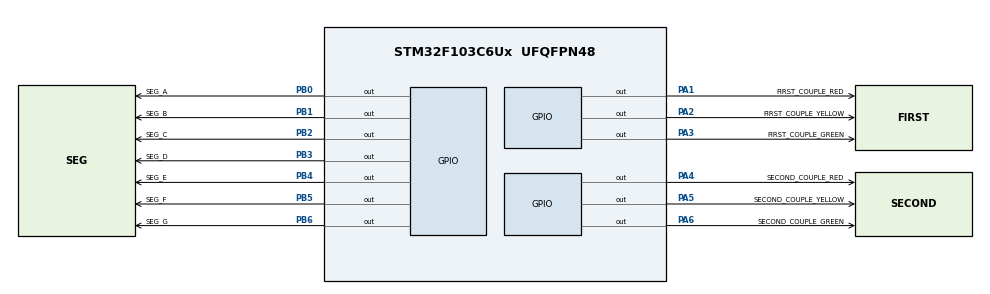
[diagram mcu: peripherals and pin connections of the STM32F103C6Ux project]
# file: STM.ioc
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Mcu.Family=STM32F1
Mcu.Name=STM32F103C6Ux
Mcu.Package=UFQFPN48
NVIC.PriorityGroup=NVIC_PRIORITYGROUP_4
PA1.GPIO_Label=FIRST_COUPLE_RED
PA1.Signal=GPIO_Output
PA2.GPIO_Label=FIRST_COUPLE_YELLOW
PA2.Signal=GPIO_Output
PA3.GPIO_Label=FIRST_COUPLE_GREEN
PA3.Signal=GPIO_Output
PA4.GPIO_Label=SECOND_COUPLE_RED
PA4.Signal=GPIO_Output
PA5.GPIO_Label=SECOND_COUPLE_YELLOW
PA5.Signal=GPIO_Output
PA6.GPIO_Label=SECOND_COUPLE_GREEN
PA6.Signal=GPIO_Output
PB0.GPIO_Label=SEG_A
PB0.Signal=GPIO_Output
PB1.GPIO_Label=SEG_B
PB1.Signal=GPIO_Output
PB2.GPIO_Label=SEG_C
PB2.Signal=GPIO_Output
PB3.GPIO_Label=SEG_D
PB3.Signal=GPIO_Output
PB4.GPIO_Label=SEG_E
PB4.Signal=GPIO_Output
PB5.GPIO_Label=SEG_F
PB5.Signal=GPIO_Output
PB6.GPIO_Label=SEG_G
PB6.Signal=GPIO_Output
ProjectManager.HeapSize=0x200
ProjectManager.StackSize=0x400
ProjectManager.TargetToolchain=STM32CubeIDE
RCC.APB1Freq_Value=8000000
RCC.APB2Freq_Value=8000000
VP_SYS_VS_ND.Mode=No_Debug
board=custom

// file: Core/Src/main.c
/* USER CODE BEGIN Header */
/**
  ******************************************************************************
  * @file           : main.c
  * @brief          : Main program body
  ******************************************************************************
  * @attention
  *
  * <h2><center>&copy; Copyright (c) 2022 STMicroelectronics.
  * All rights reserved.</center></h2>
  *
  * This software component is licensed by ST under BSD 3-Clause license,
  * the "License"; You may not use this file except in compliance with the
  * License. You may obtain a copy of the License at:
  *                        opensource.org/licenses/BSD-3-Clause
  *
  ******************************************************************************
  */
/* USER CODE END Header */
#include "main.h"

/* USER CODE BEGIN PTD */
enum LedState { RED_STATE , YELLOW_STATE , GREEN_STATE } ;
/* USER CODE END PTD */

/* USER CODE BEGIN PD */
#define SECOND 2000
/* USER CODE END PD */

void SystemClock_Config(void);
static void MX_GPIO_Init(void);

void display7SEG(int num){
	  switch(num){
		  case 0:
			  HAL_GPIO_WritePin ( SEG_A_GPIO_Port , SEG_A_Pin , 0 ) ;
			  HAL_GPIO_WritePin ( SEG_B_GPIO_Port , SEG_B_Pin , 0 ) ;
			  HAL_GPIO_WritePin ( SEG_C_GPIO_Port , SEG_C_Pin , 0 ) ;
			  HAL_GPIO_WritePin ( SEG_D_GPIO_Port , SEG_D_Pin , 0 ) ;
			  HAL_GPIO_WritePin ( SEG_E_GPIO_Port , SEG_E_Pin , 0 ) ;
			  HAL_GPIO_WritePin ( SEG_F_GPIO_Port , SEG_F_Pin , 0 ) ;
			  HAL_GPIO_WritePin ( SEG_G_GPIO_Port , SEG_G_Pin , 1 ) ;
			  break;

		case 1:
			  HAL_GPIO_WritePin ( SEG_A_GPIO_Port , SEG_A_Pin , 1 ) ;
			  HAL_GPIO_WritePin ( SEG_B_GPIO_Port , SEG_B_Pin , 0 ) ;
			  HAL_GPIO_WritePin ( SEG_C_GPIO_Port , SEG_C_Pin , 0 ) ;
			  HAL_GPIO_WritePin ( SEG_D_GPIO_Port , SEG_D_Pin , 1 ) ;
			  HAL_GPIO_WritePin ( SEG_E_GPIO_Port , SEG_E_Pin , 1 ) ;
			  HAL_GPIO_WritePin ( SEG_F_GPIO_Port , SEG_F_Pin , 1 ) ;
			  HAL_GPIO_WritePin ( SEG_G_GPIO_Port , SEG_G_Pin , 1 ) ;
			  break;

			case 2:
			  HAL_GPIO_WritePin ( SEG_A_GPIO_Port , SEG_A_Pin , 0 ) ;
			  HAL_GPIO_WritePin ( SEG_B_GPIO_Port , SEG_B_Pin , 0 ) ;
			  HAL_GPIO_WritePin ( SEG_C_GPIO_Port , SEG_C_Pin , 1 ) ;
			  HAL_GPIO_WritePin ( SEG_D_GPIO_Port , SEG_D_Pin , 0 ) ;
			  HAL_GPIO_WritePin ( SEG_E_GPIO_Port , SEG_E_Pin , 0 ) ;
			  HAL_GPIO_WritePin ( SEG_F_GPIO_Port , SEG_F_Pin , 1 ) ;
			  HAL_GPIO_WritePin ( SEG_G_GPIO_Port , SEG_G_Pin , 0 ) ;
			  break;

			case 3:
			  HAL_GPIO_WritePin ( SEG_A_GPIO_Port , SEG_A_Pin , 0 ) ;
			  HAL_GPIO_WritePin ( SEG_B_GPIO_Port , SEG_B_Pin , 0 ) ;
			  HAL_GPIO_WritePin ( SEG_C_GPIO_Port , SEG_C_Pin , 0 ) ;
			  HAL_GPIO_WritePin ( SEG_D_GPIO_Port , SEG_D_Pin , 0 ) ;
			  HAL_GPIO_WritePin ( SEG_E_GPIO_Port , SEG_E_Pin , 1 ) ;
			  HAL_GPIO_WritePin ( SEG_F_GPIO_Port , SEG_F_Pin , 1 ) ;
			  HAL_GPIO_WritePin ( SEG_G_GPIO_Port , SEG_G_Pin , 0 ) ;
			  break;

			case 4:
			  HAL_GPIO_WritePin ( SEG_A_GPIO_Port , SEG_A_Pin , 1 ) ;
			  HAL_GPIO_WritePin ( SEG_B_GPIO_Port , SEG_B_Pin , 0 ) ;
			  HAL_GPIO_WritePin ( SEG_C_GPIO_Port , SEG_C_Pin , 0 ) ;
			  HAL_GPIO_WritePin ( SEG_D_GPIO_Port , SEG_D_Pin , 1 ) ;
			  HAL_GPIO_WritePin ( SEG_E_GPIO_Port , SEG_E_Pin , 1 ) ;
			  HAL_GPIO_WritePin ( SEG_F_GPIO_Port , SEG_F_Pin , 0 ) ;
			  HAL_GPIO_WritePin ( SEG_G_GPIO_Port , SEG_G_Pin , 0 ) ;
			  break;
			case 5:
			  HAL_GPIO_WritePin ( SEG_A_GPIO_Port , SEG_A_Pin , 0 ) ;
			  HAL_GPIO_WritePin ( SEG_B_GPIO_Port , SEG_B_Pin , 1 ) ;
			  HAL_GPIO_WritePin ( SEG_C_GPIO_Port , SEG_C_Pin , 0 ) ;
			  HAL_GPIO_WritePin ( SEG_D_GPIO_Port , SEG_D_Pin , 0 ) ;
			  HAL_GPIO_WritePin ( SEG_E_GPIO_Port , SEG_E_Pin , 1 ) ;
			  HAL_GPIO_WritePin ( SEG_F_GPIO_Port , SEG_F_Pin , 0 ) ;
			  HAL_GPIO_WritePin ( SEG_G_GPIO_Port , SEG_G_Pin , 0 ) ;
			  break;
			case 6:
			  HAL_GPIO_WritePin ( SEG_A_GPIO_Port , SEG_A_Pin , 0 ) ;
			  HAL_GPIO_WritePin ( SEG_B_GPIO_Port , SEG_B_Pin , 1 ) ;
			  HAL_GPIO_WritePin ( SEG_C_GPIO_Port , SEG_C_Pin , 0 ) ;
			  HAL_GPIO_WritePin ( SEG_D_GPIO_Port , SEG_D_Pin , 0 ) ;
			  HAL_GPIO_WritePin ( SEG_E_GPIO_Port , SEG_E_Pin , 0 ) ;
			  HAL_GPIO_WritePin ( SEG_F_GPIO_Port , SEG_F_Pin , 0 ) ;
			  HAL_GPIO_WritePin ( SEG_G_GPIO_Port , SEG_G_Pin , 0 ) ;
			  break;
			case 7:
			  HAL_GPIO_WritePin ( SEG_A_GPIO_Port , SEG_A_Pin , 0 ) ;
			  HAL_GPIO_WritePin ( SEG_B_GPIO_Port , SEG_B_Pin , 0 ) ;
			  HAL_GPIO_WritePin ( SEG_C_GPIO_Port , SEG_C_Pin , 0 ) ;
			  HAL_GPIO_WritePin ( SEG_D_GPIO_Port , SEG_D_Pin , 1 ) ;
			  HAL_GPIO_WritePin ( SEG_E_GPIO_Port , SEG_E_Pin , 1 ) ;
			  HAL_GPIO_WritePin ( SEG_F_GPIO_Port , SEG_F_Pin , 1 ) ;
			  HAL_GPIO_WritePin ( SEG_G_GPIO_Port , SEG_G_Pin , 1 ) ;
			  break;
			case 8:
			  HAL_GPIO_WritePin ( SEG_A_GPIO_Port , SEG_A_Pin , 0 ) ;
			  HAL_GPIO_WritePin ( SEG_B_GPIO_Port , SEG_B_Pin , 0 ) ;
			  HAL_GPIO_WritePin ( SEG_C_GPIO_Port , SEG_C_Pin , 0 ) ;
			  HAL_GPIO_WritePin ( SEG_D_GPIO_Port , SEG_D_Pin , 0 ) ;
			  HAL_GPIO_WritePin ( SEG_E_GPIO_Port , SEG_E_Pin , 0 ) ;
			  HAL_GPIO_WritePin ( SEG_F_GPIO_Port , SEG_F_Pin , 0 ) ;
			  HAL_GPIO_WritePin ( SEG_G_GPIO_Port , SEG_G_Pin , 0 ) ;
			  break;
			case 9:
			  HAL_GPIO_WritePin ( SEG_A_GPIO_Port , SEG_A_Pin , 0 ) ;
			  HAL_GPIO_WritePin ( SEG_B_GPIO_Port , SEG_B_Pin , 0 ) ;
			  HAL_GPIO_WritePin ( SEG_C_GPIO_Port , SEG_C_Pin , 0 ) ;
			  HAL_GPIO_WritePin ( SEG_D_GPIO_Port , SEG_D_Pin , 0 ) ;
			  HAL_GPIO_WritePin ( SEG_E_GPIO_Port , SEG_E_Pin , 1 ) ;
			  HAL_GPIO_WritePin ( SEG_F_GPIO_Port , SEG_F_Pin , 0 ) ;
			  HAL_GPIO_WritePin ( SEG_G_GPIO_Port , SEG_G_Pin , 0 ) ;
			  break;
			default:
				break;
	  }
}
int main(void)
{

  /* MCU Configuration--------------------------------------------------------*/

  /* Reset of all peripherals, Initializes the Flash interface and the Systick. */
  HAL_Init();

  /* Configure the system clock */
  SystemClock_Config();

  /* Initialize all configured peripherals */
  MX_GPIO_Init();

  /* Infinite loop */
  /* USER CODE BEGIN WHILE */
  int counter = 0;
  while (1)
  {
	  if( counter >= 10) counter = 0;
	  display7SEG( counter ++) ;
	  HAL_Delay(1000) ;
    /* USER CODE END WHILE */

  }
}

void SystemClock_Config(void)
{
  RCC_OscInitTypeDef RCC_OscInitStruct = {0};
  RCC_ClkInitTypeDef RCC_ClkInitStruct = {0};

  /** Initializes the RCC Oscillators according to the specified parameters
  * in the RCC_OscInitTypeDef structure.
  */
  RCC_OscInitStruct.OscillatorType = RCC_OSCILLATORTYPE_HSI;
  RCC_OscInitStruct.HSIState = RCC_HSI_ON;
  RCC_OscInitStruct.HSICalibrationValue = RCC_HSICALIBRATION_DEFAULT;
  RCC_OscInitStruct.PLL.PLLState = RCC_PLL_NONE;
  if (HAL_RCC_OscConfig(&RCC_OscInitStruct) != HAL_OK)
  {
    Error_Handler();
  }
  /** Initializes the CPU, AHB and APB buses clocks
  */
  RCC_ClkInitStruct.ClockType = RCC_CLOCKTYPE_HCLK|RCC_CLOCKTYPE_SYSCLK
                              |RCC_CLOCKTYPE_PCLK1|RCC_CLOCKTYPE_PCLK2;
  RCC_ClkInitStruct.SYSCLKSource = RCC_SYSCLKSOURCE_HSI;
  RCC_ClkInitStruct.AHBCLKDivider = RCC_SYSCLK_DIV1;
  RCC_ClkInitStruct.APB1CLKDivider = RCC_HCLK_DIV1;
  RCC_ClkInitStruct.APB2CLKDivider = RCC_HCLK_DIV1;

  if (HAL_RCC_ClockConfig(&RCC_ClkInitStruct, FLASH_LATENCY_0) != HAL_OK)
  {
    Error_Handler();
  }
}

static void MX_GPIO_Init(void)
{
  GPIO_InitTypeDef GPIO_InitStruct = {0};

  /* GPIO Ports Clock Enable */
  __HAL_RCC_GPIOA_CLK_ENABLE();
  __HAL_RCC_GPIOB_CLK_ENABLE();

  /*Configure GPIO pin Output Level */
  HAL_GPIO_WritePin(GPIOA, FIRST_COUPLE_RED_Pin|FIRST_COUPLE_YELLOW_Pin|FIRST_COUPLE_GREEN_Pin|SECOND_COUPLE_RED_Pin
                          |SECOND_COUPLE_YELLOW_Pin|SECOND_COUPLE_GREEN_Pin, GPIO_PIN_RESET);

  /*Configure GPIO pin Output Level */
  HAL_GPIO_WritePin(GPIOB, SEG_A_Pin|SEG_B_Pin|SEG_C_Pin|SEG_D_Pin
                          |SEG_E_Pin|SEG_F_Pin|SEG_G_Pin, GPIO_PIN_RESET);

  /*Configure GPIO pins : FIRST_COUPLE_RED_Pin FIRST_COUPLE_YELLOW_Pin FIRST_COUPLE_GREEN_Pin SECOND_COUPLE_RED_Pin
                           SECOND_COUPLE_YELLOW_Pin SECOND_COUPLE_GREEN_Pin */
  GPIO_InitStruct.Pin = FIRST_COUPLE_RED_Pin|FIRST_COUPLE_YELLOW_Pin|FIRST_COUPLE_GREEN_Pin|SECOND_COUPLE_RED_Pin
                          |SECOND_COUPLE_YELLOW_Pin|SECOND_COUPLE_GREEN_Pin;
  GPIO_InitStruct.Mode = GPIO_MODE_OUTPUT_PP;
  GPIO_InitStruct.Pull = GPIO_NOPULL;
  GPIO_InitStruct.Speed = GPIO_SPEED_FREQ_LOW;
  HAL_GPIO_Init(GPIOA, &GPIO_InitStruct);

  /*Configure GPIO pins : SEG_A_Pin SEG_B_Pin SEG_C_Pin SEG_D_Pin
                           SEG_E_Pin SEG_F_Pin SEG_G_Pin */
  GPIO_InitStruct.Pin = SEG_A_Pin|SEG_B_Pin|SEG_C_Pin|SEG_D_Pin
                          |SEG_E_Pin|SEG_F_Pin|SEG_G_Pin;
  GPIO_InitStruct.Mode = GPIO_MODE_OUTPUT_PP;
  GPIO_InitStruct.Pull = GPIO_NOPULL;
  GPIO_InitStruct.Speed = GPIO_SPEED_FREQ_LOW;
  HAL_GPIO_Init(GPIOB, &GPIO_InitStruct);

}

void Error_Handler(void)
{
  __disable_irq();
  while (1)
  {
  }
}

/************************ (C) COPYRIGHT STMicroelectronics *****END OF FILE****/
